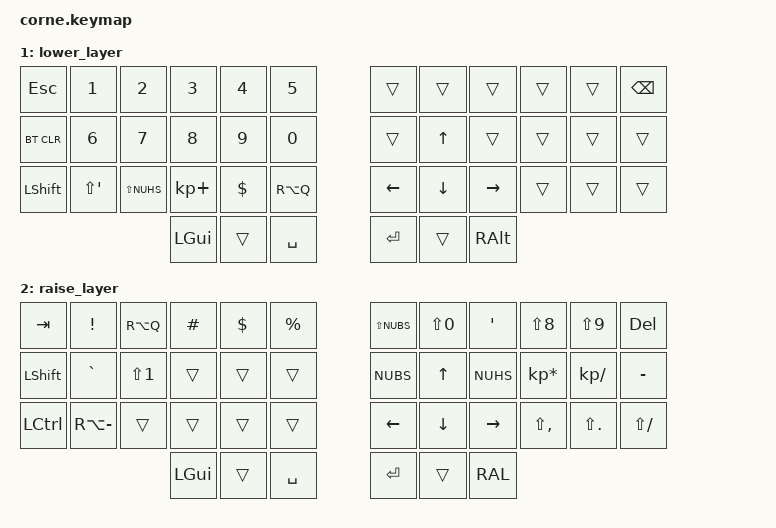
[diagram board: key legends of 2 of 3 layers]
/*
 * Copyright (c) 2020 The ZMK Contributors
 *
 * SPDX-License-Identifier: MIT
 */

#include <behaviors.dtsi>
#include <dt-bindings/zmk/keys.h>
#include <dt-bindings/zmk/bt.h>

/ {
        keymap {
                compatible = "zmk,keymap";

                default_layer {
// -----------------------------------------------------------------------------------------
// |  TAB |  Q  |  W  |  E  |  R  |  T  |   |  Y  |  U   |  I  |  O  |  P  | BSPC |
// | CTRL |  A  |  S  |  D  |  F  |  G  |   |  H  |  J   |  K  |  L  |  Ñ  |  "   |
// | SHFT |  Z  |  X  |  C  |  V  |  B  |   |  N  |  M   |  /  |  ,  |  .  |  -   |
//                    | GUI | LWR | SPC |   | ENT | RSE  | ALT |
                        bindings = <
   &kp TAB   &kp Q &kp W &kp E &kp R &kp T   &kp Y &kp U  &kp I     &kp O    &kp P    &kp BSPC
   &kp LSHFT &kp A &kp S &kp D &kp F &kp G   &kp H &kp J  &kp K     &kp L    &kp SEMI &kp LS(N2)
   &kp LCTRL &kp Z &kp X &kp C &kp V &kp B   &kp N &kp M  &kp FSLH  &kp DOT  &kp COMMA &kp &kp FSLH
                  &kp LGUI &mo 1 &kp SPACE   &kp RET &mo 2 &kp RALT
                        >;
                };
                lower_layer {
// -----------------------------------------------------------------------------------------
// | ESC  |   1  |   2   |   3   |  4  |  5  |    |     |     |     |     |     | BSPC |
// | BTCLR|   6  |   7   |   8   |  9  |  0  |    |     |  UP |     |     |     |      |
// | SHFT |   [  |   ]   |   +   |  $  |  @  |    | LFT | DWN | RGT |     |     |      |
//                         | GUI |     | SPC |   | ENT |     | ALT |

                        bindings = <
   &kp ESC     &kp N1        &kp N2        &kp N3       &kp N4    &kp N5      &trans    &trans    &trans    &trans  &trans &kp BSPC
   &bt BT_CLR  &kp N6        &kp N7        &kp N8       &kp N9    &kp N0      &trans    &kp UP    &trans    &trans  &trans &trans
   &kp LSHFT   &kp LS(APOS)  &kp LS(NUHS)  &kp KP_PLUS  &kp DLLR  &kp RA(Q)   &kp LEFT  &kp DOWN  &kp RIGHT &trans  &trans &trans
                                      &kp LGUI     &trans       &kp SPACE      &kp RET  &trans   &kp RALT

                        >;
                };

                raise_layer {
/ -----------------------------------------------------------------------------------------
// |  TAB |  !  |  @  |  #  |  $  |  %  |   |  >  |  =  |  }  |  (  |  )  | DEL  |
// | CTRL |  |  |  !  |     |     |     |   |  <  |  UP |  {  |  *  |  /  |  '   |
// | SHFT |  \  |     |     |     |     |   | LFT | DWN | RGT |  ;  |  :  |  _   |
//                    | GUI |     | SPC |   | ENT |     | ALT |

                        bindings = <
   &kp TAB   &kp EXCL       &kp RA(Q)     &kp HASH  &kp DLLR  &kp PRCNT  &kp LS(NUBS)  &kp LS(N0)  &kp APOS   &kp LS(N8)       &kp LS(N9)     &kp DEL
   &kp LSHFT &kp GRAVE      &kp LS(N1)    &trans    &trans    &trans     &kp NUBS      &kp UP      &kp NUHS   &kp KP_MULTIPLY  &kp KP_DIVIDE  &kp MINUS
   &kp LCTRL &kp RA(MINUS)  &trans        &trans    &trans    &trans     &kp LEFT      &kp DOWN    &kp RIGHT  &kp LS(COMMA)    &kp LS(DOT)    &kp LS(FSLH) 
                                        &kp LGUI &trans   &kp SPACE      &kp RET   &trans    &kp RAL
                        >;
                };
        };
};
